# DDR16SS_DDR16SS_CTLPHY_WRAP_CTL_CFG_CTLCFG_0F308000h register map
Vendor: Texas Instruments
Registers are 32-bit, read-write, reset 0x0 unless marked. A register's access mark holds for its fields unless they carry their own. Offsets are as the file gives them; [hi:lo] are bit positions; lines under a group give offsets from that group; {n}, {i} and the like mark numbered series.

## DDR16SS_CTLPHY_WRAP_CTL_CFG_CTLCFG (part 6 of 11)
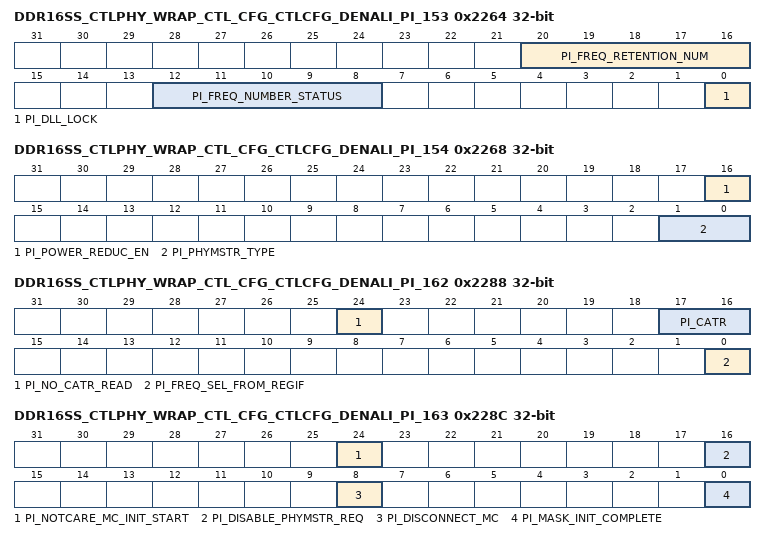
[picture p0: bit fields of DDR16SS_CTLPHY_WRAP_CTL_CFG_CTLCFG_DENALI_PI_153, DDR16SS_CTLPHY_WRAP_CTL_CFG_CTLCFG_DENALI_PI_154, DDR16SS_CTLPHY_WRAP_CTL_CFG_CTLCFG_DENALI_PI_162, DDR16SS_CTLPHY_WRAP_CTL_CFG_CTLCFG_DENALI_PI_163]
0x2264 DDR16SS_CTLPHY_WRAP_CTL_CFG_CTLCFG_DENALI_PI_153 access per field
  [20:16] PI_FREQ_RETENTION_NUM rw — Monitor active freq number in PI for data_retention Reset Source: ctl_amod_g_rst_n
  [12:8] PI_FREQ_NUMBER_STATUS ro — Monitor active freq number in PI. READ-ONLY. Reset Source: ctl_amod_g_rst_n
  [0] PI_DLL_LOCK ro — Monitor dfi_init_complete from PHY. READ-ONLY. Reset Source: ctl_amod_g_rst_n
0x2268 DDR16SS_CTLPHY_WRAP_CTL_CFG_CTLCFG_DENALI_PI_154
  [16] PI_POWER_REDUC_EN — PI Power reduction enable, 1 = enabled. Reset Source: ctl_amod_g_rst_n
  [1:0] PI_PHYMSTR_TYPE — Defines how the controller should set the state of DRAM before turning control of the DFI bus over to the PI. Reset Source: ctl_amod_g_rst_n
{0x2000+4i} DDR16SS_CTLPHY_WRAP_CTL_CFG_CTLCFG_DENALI_PI_{i} access not given reset not defined (i=155..158)
0x227C DDR16SS_CTLPHY_WRAP_CTL_CFG_CTLCFG_DENALI_PI_159
  [23:16] PI_WRLVL_MAX_STROBE_PEND — Defines the maximum number of wrlvl_strobes that be accumulated before an AREF is prevented from being generated. Reset Source: ctl_amod_g_rst_n
0x2280 DDR16SS_CTLPHY_WRAP_CTL_CFG_CTLCFG_DENALI_PI_160
  [8:0] PI_TREFBW_THR — Threshold value to control the AREF command interval. When the number of pending AREF is over this value, the interval is expanded to be tREF/8. Reset Source: ctl_amod_g_rst_n
0x2284 DDR16SS_CTLPHY_WRAP_CTL_CFG_CTLCFG_DENALI_PI_161
  [4:0] PI_FREQ_CHANGE_REG_COPY — In non-DFI 4.0 mode, contains the frequency copy value. Reset Source: ctl_amod_g_rst_n
0x2288 DDR16SS_CTLPHY_WRAP_CTL_CFG_CTLCFG_DENALI_PI_162
  [24] PI_NO_CATR_READ — Defines how the LPDDR4 termination status is determined. 1: PI use PI_CATR to get DRAM CA Termination status. 0: PI reads DRAM MR0.OP7 to get DRAM CA Termination status. Reset Source: ctl_amod_g_rst_n
  [17:16] PI_CATR — It indicates LP4 DRAM CA terminition ON/OFF state. Each bit corresponds to each chip select. 1:ON 0:OFF. This parameter is active when PI_NO_CATR_READ==1. When PI_NO_CATR_READ==0, this param is inactive Reset Source: ctl_amod_g_rst_n
  [0] PI_FREQ_SEL_FROM_REGIF — In non-DFI 4.0 mode, user select the frequency copies from pi_freq_change_reg_copy. Reset Source: ctl_amod_g_rst_n
0x228C DDR16SS_CTLPHY_WRAP_CTL_CFG_CTLCFG_DENALI_PI_163
  [24] PI_NOTCARE_MC_INIT_START — Defines whether PI waits for the controller to initiate dfi_init_start before PI memory initialization, 1: wait for dfi_init_start Reset Source: ctl_amod_g_rst_n
  [16] PI_DISABLE_PHYMSTR_REQ — PI mask dfi_phymstr_req to the controller and get dfi bus without dfi_phymstr_ack, 1: disconnect Reset Source: ctl_amod_g_rst_n
  [8] PI_DISCONNECT_MC — PI disconnects the controller from the PHY, 1: disconnect Reset Source: ctl_amod_g_rst_n
  [0] PI_MASK_INIT_COMPLETE — Enable the masking of the dfi_init_complete signal back to the controller, 1: mask. Reset Source: ctl_amod_g_rst_n
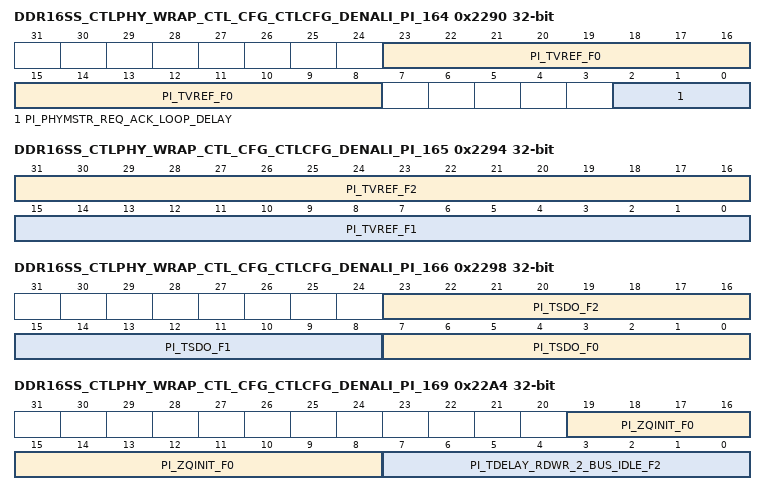
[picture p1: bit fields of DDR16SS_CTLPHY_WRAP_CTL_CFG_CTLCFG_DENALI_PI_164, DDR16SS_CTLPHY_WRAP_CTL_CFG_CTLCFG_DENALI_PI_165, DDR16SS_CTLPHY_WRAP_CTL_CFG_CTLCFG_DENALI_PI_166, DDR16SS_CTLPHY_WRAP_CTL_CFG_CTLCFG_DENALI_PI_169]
0x2290 DDR16SS_CTLPHY_WRAP_CTL_CFG_CTLCFG_DENALI_PI_164
  [23:8] PI_TVREF_F0 — Defines the number of cycles that the PI should wait before issuing the next command after a VREF training MRW command for frequency set 0. Reset Source: ctl_amod_g_rst_n
  [2:0] PI_PHYMSTR_REQ_ACK_LOOP_DELAY — The delay between phymstr_req and inner phymstr_ack when PI_DISABLE_PHYMSTR_REQ set 1 Reset Source: ctl_amod_g_rst_n
0x2294 DDR16SS_CTLPHY_WRAP_CTL_CFG_CTLCFG_DENALI_PI_165
  [31:16] PI_TVREF_F2 — Defines the number of cycles that the PI should wait before issuing the next command after a VREF training MRW command for frequency set 2. Reset Source: ctl_amod_g_rst_n
  [15:0] PI_TVREF_F1 — Defines the number of cycles that the PI should wait before issuing the next command after a VREF training MRW command for frequency set 1. Reset Source: ctl_amod_g_rst_n
0x2298 DDR16SS_CTLPHY_WRAP_CTL_CFG_CTLCFG_DENALI_PI_166
  [23:16] PI_TSDO_F2 — The delay from the read preamble training MRS command to the data strobe drive out for frequency set 2, in PI clocks Reset Source: ctl_amod_g_rst_n
  [15:8] PI_TSDO_F1 — The delay from the read preamble training MRS command to the data strobe drive out for frequency set 1, in PI clocks Reset Source: ctl_amod_g_rst_n
  [7:0] PI_TSDO_F0 — The delay from the read preamble training MRS command to the data strobe drive out for frequency set 0, in PI clocks Reset Source: ctl_amod_g_rst_n
0x229C DDR16SS_CTLPHY_WRAP_CTL_CFG_CTLCFG_DENALI_PI_167
  [7:0] PI_TDELAY_RDWR_2_BUS_IDLE_F0 — The delay from read or write to bus idle for frequency set 0. Recommend setting is: delay time from read command issued to last read data received. Reset Source: ctl_amod_g_rst_n
0x22A0 DDR16SS_CTLPHY_WRAP_CTL_CFG_CTLCFG_DENALI_PI_168
  [7:0] PI_TDELAY_RDWR_2_BUS_IDLE_F1 — The delay from read or write to bus idle for frequency set 1. Recommend setting is: delay time from read command issued to last read data received. Reset Source: ctl_amod_g_rst_n
0x22A4 DDR16SS_CTLPHY_WRAP_CTL_CFG_CTLCFG_DENALI_PI_169
  [19:8] PI_ZQINIT_F0 — Number of cycles needed for a ZQINIT command for frequency set 0. Reset Source: ctl_amod_g_rst_n
  [7:0] PI_TDELAY_RDWR_2_BUS_IDLE_F2 — The delay from read or write to bus idle for frequency set 2. Recommend setting is: delay time from read command issued to last read data received. Reset Source: ctl_amod_g_rst_n
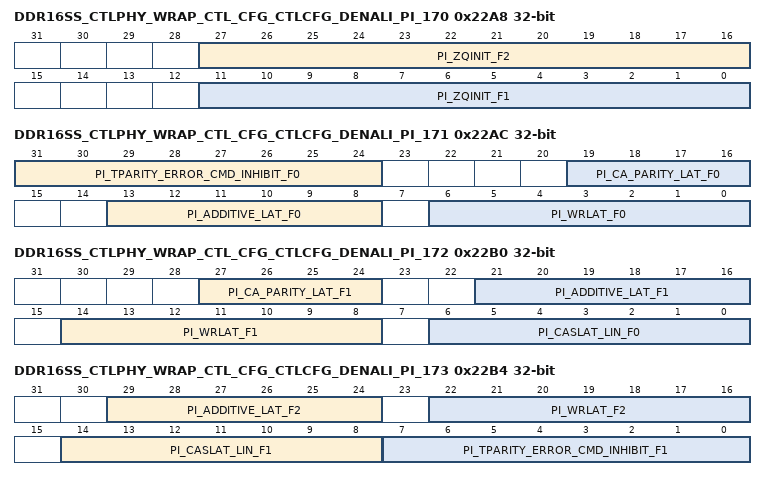
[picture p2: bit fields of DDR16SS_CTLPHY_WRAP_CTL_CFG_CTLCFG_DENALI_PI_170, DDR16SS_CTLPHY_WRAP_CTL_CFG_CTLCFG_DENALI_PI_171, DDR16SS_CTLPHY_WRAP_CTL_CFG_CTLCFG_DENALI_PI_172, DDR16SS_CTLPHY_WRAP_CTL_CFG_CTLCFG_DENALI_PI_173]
0x22A8 DDR16SS_CTLPHY_WRAP_CTL_CFG_CTLCFG_DENALI_PI_170
  [27:16] PI_ZQINIT_F2 — Number of cycles needed for a ZQINIT command for frequency set 2. Reset Source: ctl_amod_g_rst_n
  [11:0] PI_ZQINIT_F1 — Number of cycles needed for a ZQINIT command for frequency set 1. Reset Source: ctl_amod_g_rst_n
0x22AC DDR16SS_CTLPHY_WRAP_CTL_CFG_CTLCFG_DENALI_PI_171
  [31:24] PI_TPARITY_ERROR_CMD_INHIBIT_F0 — Defines the window after the PI receives a parity error during which DRAM commands will not execute for frequency set 0. Reset Source: ctl_amod_g_rst_n
  [19:16] PI_CA_PARITY_LAT_F0 — DRAM CA parity latency value in cycles for frequency set 0. Reset Source: ctl_amod_g_rst_n
  [13:8] PI_ADDITIVE_LAT_F0 — DRAM additive latency value in cycles for frequency set 0. Reset Source: ctl_amod_g_rst_n
  [6:0] PI_WRLAT_F0 — DRAM WRLAT value in cycles for frequency set 0. Reset Source: ctl_amod_g_rst_n
0x22B0 DDR16SS_CTLPHY_WRAP_CTL_CFG_CTLCFG_DENALI_PI_172
  [27:24] PI_CA_PARITY_LAT_F1 — DRAM CA parity latency value in cycles for frequency set 1. Reset Source: ctl_amod_g_rst_n
  [21:16] PI_ADDITIVE_LAT_F1 — DRAM additive latency value in cycles for frequency set 1. Reset Source: ctl_amod_g_rst_n
  [14:8] PI_WRLAT_F1 — DRAM WRLAT value in cycles for frequency set 1. Reset Source: ctl_amod_g_rst_n
  [6:0] PI_CASLAT_LIN_F0 — Sets latency from read command sent to data received from/to controller for frequency set 0. Bit [0] is half-cycle increment and the upper bits define memory CAS latency for the controller. Reset Source: ctl_amod_g_rst_n
0x22B4 DDR16SS_CTLPHY_WRAP_CTL_CFG_CTLCFG_DENALI_PI_173
  [29:24] PI_ADDITIVE_LAT_F2 — DRAM additive latency value in cycles for frequency set 2. Reset Source: ctl_amod_g_rst_n
  [22:16] PI_WRLAT_F2 — DRAM WRLAT value in cycles for frequency set 2. Reset Source: ctl_amod_g_rst_n
  [14:8] PI_CASLAT_LIN_F1 — Sets latency from read command sent to data received from/to controller for frequency set 1. Bit [0] is half-cycle increment and the upper bits define memory CAS latency for the controller. Reset Source: ctl_amod_g_rst_n
  [7:0] PI_TPARITY_ERROR_CMD_INHIBIT_F1 — Defines the window after the PI receives a parity error during which DRAM commands will not execute for frequency set 1. Reset Source: ctl_amod_g_rst_n
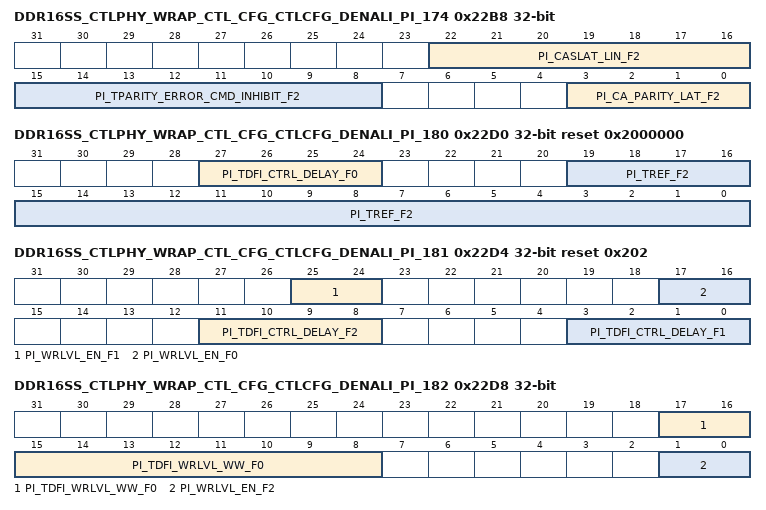
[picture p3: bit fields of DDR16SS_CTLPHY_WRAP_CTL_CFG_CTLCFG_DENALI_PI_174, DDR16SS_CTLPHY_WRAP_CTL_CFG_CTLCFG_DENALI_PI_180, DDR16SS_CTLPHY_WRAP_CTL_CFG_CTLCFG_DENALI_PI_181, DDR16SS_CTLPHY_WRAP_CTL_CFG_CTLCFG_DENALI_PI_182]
0x22B8 DDR16SS_CTLPHY_WRAP_CTL_CFG_CTLCFG_DENALI_PI_174
  [22:16] PI_CASLAT_LIN_F2 — Sets latency from read command sent to data received from/to controller for frequency set 2. Bit [0] is half-cycle increment and the upper bits define memory CAS latency for the controller. Reset Source: ctl_amod_g_rst_n
  [15:8] PI_TPARITY_ERROR_CMD_INHIBIT_F2 — Defines the window after the PI receives a parity error during which DRAM commands will not execute for frequency set 2. Reset Source: ctl_amod_g_rst_n
  [3:0] PI_CA_PARITY_LAT_F2 — DRAM CA parity latency value in cycles for frequency set 2. Reset Source: ctl_amod_g_rst_n
0x22BC DDR16SS_CTLPHY_WRAP_CTL_CFG_CTLCFG_DENALI_PI_175
  [9:0] PI_TRFC_F0 — DRAM tRFC value in memory clocks for frequency set 0. Reset Source: ctl_amod_g_rst_n
0x22C0 DDR16SS_CTLPHY_WRAP_CTL_CFG_CTLCFG_DENALI_PI_176
  [19:0] PI_TREF_F0 — DRAM tREF value in memory clocks for frequency set 0. Reset Source: ctl_amod_g_rst_n
0x22C4 DDR16SS_CTLPHY_WRAP_CTL_CFG_CTLCFG_DENALI_PI_177
  [9:0] PI_TRFC_F1 — DRAM tRFC value in memory clocks for frequency set 1. Reset Source: ctl_amod_g_rst_n
0x22C8 DDR16SS_CTLPHY_WRAP_CTL_CFG_CTLCFG_DENALI_PI_178
  [19:0] PI_TREF_F1 — DRAM tREF value in memory clocks for frequency set 1. Reset Source: ctl_amod_g_rst_n
0x22CC DDR16SS_CTLPHY_WRAP_CTL_CFG_CTLCFG_DENALI_PI_179
  [9:0] PI_TRFC_F2 — DRAM tRFC value in memory clocks for frequency set 2. Reset Source: ctl_amod_g_rst_n
0x22D0 DDR16SS_CTLPHY_WRAP_CTL_CFG_CTLCFG_DENALI_PI_180 reset 0x2000000
  [27:24] PI_TDFI_CTRL_DELAY_F0 — Defines the DFI tCTRL_DELAY timing parameter [in DFI clocks] for frequency set 0, the delay between a DFI command change and a memory command. Reset Source: ctl_amod_g_rst_n
  [19:0] PI_TREF_F2 — DRAM tREF value in memory clocks for frequency set 2. Reset Source: ctl_amod_g_rst_n
0x22D4 DDR16SS_CTLPHY_WRAP_CTL_CFG_CTLCFG_DENALI_PI_181 reset 0x202
  [25:24] PI_WRLVL_EN_F1 — Enable the PI write leveling module for frequency set 1. Bit[1] represents the support when non-initialization. Bit[0]represents the support when initialization. Set to 1 to enable. Reset Source: ctl_amod_g_rst_n
  [17:16] PI_WRLVL_EN_F0 — Enable the PI write leveling module for frequency set 0. Bit[1] represents the support when non-initialization. Bit[0]represents the support when initialization. Set to 1 to enable. Reset Source: ctl_amod_g_rst_n
  [11:8] PI_TDFI_CTRL_DELAY_F2 — Defines the DFI tCTRL_DELAY timing parameter [in DFI clocks] for frequency set 2, the delay between a DFI command change and a memory command. Reset Source: ctl_amod_g_rst_n
  [3:0] PI_TDFI_CTRL_DELAY_F1 — Defines the DFI tCTRL_DELAY timing parameter [in DFI clocks] for frequency set 1, the delay between a DFI command change and a memory command. Reset Source: ctl_amod_g_rst_n
0x22D8 DDR16SS_CTLPHY_WRAP_CTL_CFG_CTLCFG_DENALI_PI_182
  [17:8] PI_TDFI_WRLVL_WW_F0 — Defines the DFI tWRLVL_WW timing parameter [in DFI clocks] for frequency set 0, the minimum cycles between dfi_wrlvl_strobe assertions. Reset Source: ctl_amod_g_rst_n
  [1:0] PI_WRLVL_EN_F2 — Enable the PI write leveling module for frequency set 2. Bit[1] represents the support when non-initialization. Bit[0]represents the support when initialization. Set to 1 to enable. Reset Source: ctl_amod_g_rst_n
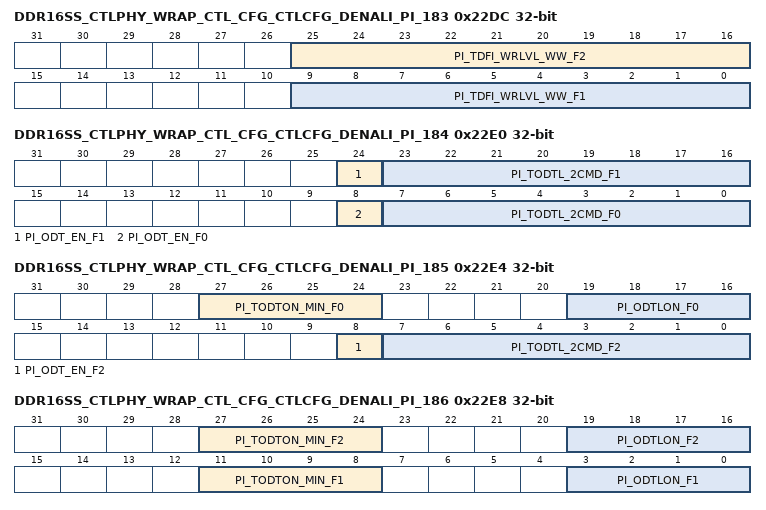
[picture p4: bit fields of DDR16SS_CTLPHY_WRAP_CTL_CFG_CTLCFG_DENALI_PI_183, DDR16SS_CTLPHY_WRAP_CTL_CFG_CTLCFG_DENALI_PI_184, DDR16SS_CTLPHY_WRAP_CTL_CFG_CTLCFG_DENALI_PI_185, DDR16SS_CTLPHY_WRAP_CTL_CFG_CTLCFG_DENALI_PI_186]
0x22DC DDR16SS_CTLPHY_WRAP_CTL_CFG_CTLCFG_DENALI_PI_183
  [25:16] PI_TDFI_WRLVL_WW_F2 — Defines the DFI tWRLVL_WW timing parameter [in DFI clocks] for frequency set 2, the minimum cycles between dfi_wrlvl_strobe assertions. Reset Source: ctl_amod_g_rst_n
  [9:0] PI_TDFI_WRLVL_WW_F1 — Defines the DFI tWRLVL_WW timing parameter [in DFI clocks] for frequency set 1, the minimum cycles between dfi_wrlvl_strobe assertions. Reset Source: ctl_amod_g_rst_n
0x22E0 DDR16SS_CTLPHY_WRAP_CTL_CFG_CTLCFG_DENALI_PI_184
  [24] PI_ODT_EN_F1 — Enable support of DRAM ODT. When enabled, PI will assert and de-assert ODT output to DRAM as needed for frequency set 1. Reset Source: ctl_amod_g_rst_n
  [23:16] PI_TODTL_2CMD_F1 — Defines the DRAM delay from an ODT de-assertion to the next non-write, non-read command for frequency set 1. Reset Source: ctl_amod_g_rst_n
  [8] PI_ODT_EN_F0 — Enable support of DRAM ODT. When enabled, PI will assert and de-assert ODT output to DRAM as needed for frequency set 0. Reset Source: ctl_amod_g_rst_n
  [7:0] PI_TODTL_2CMD_F0 — Defines the DRAM delay from an ODT de-assertion to the next non-write, non-read command for frequency set 0. Reset Source: ctl_amod_g_rst_n
0x22E4 DDR16SS_CTLPHY_WRAP_CTL_CFG_CTLCFG_DENALI_PI_185
  [27:24] PI_TODTON_MIN_F0 — Defines the point in time when the device termination circuit leaves High-Z and ODT resistance begins to turn on for frequency set 0. Reset Source: ctl_amod_g_rst_n
  [19:16] PI_ODTLON_F0 — Defines the latency from a CAS-2 command to the tODTon reference for frequency set 0. Reset Source: ctl_amod_g_rst_n
  [8] PI_ODT_EN_F2 — Enable support of DRAM ODT. When enabled, PI will assert and de-assert ODT output to DRAM as needed for frequency set 2. Reset Source: ctl_amod_g_rst_n
  [7:0] PI_TODTL_2CMD_F2 — Defines the DRAM delay from an ODT de-assertion to the next non-write, non-read command for frequency set 2. Reset Source: ctl_amod_g_rst_n
0x22E8 DDR16SS_CTLPHY_WRAP_CTL_CFG_CTLCFG_DENALI_PI_186
  [27:24] PI_TODTON_MIN_F2 — Defines the point in time when the device termination circuit leaves High-Z and ODT resistance begins to turn on for frequency set 2. Reset Source: ctl_amod_g_rst_n
  [19:16] PI_ODTLON_F2 — Defines the latency from a CAS-2 command to the tODTon reference for frequency set 2. Reset Source: ctl_amod_g_rst_n
  [11:8] PI_TODTON_MIN_F1 — Defines the point in time when the device termination circuit leaves High-Z and ODT resistance begins to turn on for frequency set 1. Reset Source: ctl_amod_g_rst_n
  [3:0] PI_ODTLON_F1 — Defines the latency from a CAS-2 command to the tODTon reference for frequency set 1. Reset Source: ctl_amod_g_rst_n
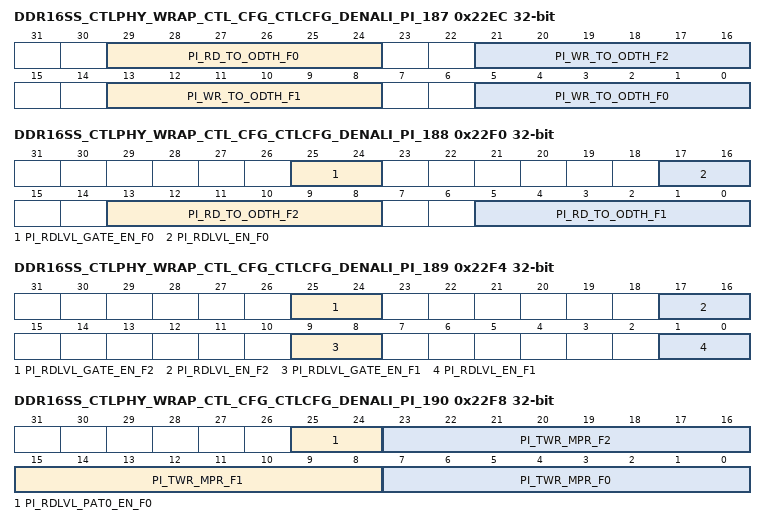
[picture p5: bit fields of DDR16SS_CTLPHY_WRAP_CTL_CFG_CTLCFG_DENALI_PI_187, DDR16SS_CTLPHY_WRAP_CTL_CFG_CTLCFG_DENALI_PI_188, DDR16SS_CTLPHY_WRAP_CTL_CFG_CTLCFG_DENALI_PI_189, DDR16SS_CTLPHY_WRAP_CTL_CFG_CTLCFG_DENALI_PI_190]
0x22EC DDR16SS_CTLPHY_WRAP_CTL_CFG_CTLCFG_DENALI_PI_187
  [29:24] PI_RD_TO_ODTH_F0 — Defines the delay from a read command to ODT assertion for frequency set 0. Reset Source: ctl_amod_g_rst_n
  [21:16] PI_WR_TO_ODTH_F2 — Defines the delay from a write command to ODT assertion for frequency set 2. Reset Source: ctl_amod_g_rst_n
  [13:8] PI_WR_TO_ODTH_F1 — Defines the delay from a write command to ODT assertion for frequency set 1. Reset Source: ctl_amod_g_rst_n
  [5:0] PI_WR_TO_ODTH_F0 — Defines the delay from a write command to ODT assertion for frequency set 0. Reset Source: ctl_amod_g_rst_n
0x22F0 DDR16SS_CTLPHY_WRAP_CTL_CFG_CTLCFG_DENALI_PI_188
  [25:24] PI_RDLVL_GATE_EN_F0 — Enable the PI gate training module for frequency set 0. Bit[1] represents the support when non-initialization. Bit[0]represents the support when initialization. Set to 1 to enable. Reset Source: ctl_amod_g_rst_n
  [17:16] PI_RDLVL_EN_F0 — Enable the PI data eye training module for frequency set 0. Bit[1] represents the support when non-initialization. Bit[0]represents the support when initialization. Set to 1 to enable. Reset Source: ctl_amod_g_rst_n
  [13:8] PI_RD_TO_ODTH_F2 — Defines the delay from a read command to ODT assertion for frequency set 2. Reset Source: ctl_amod_g_rst_n
  [5:0] PI_RD_TO_ODTH_F1 — Defines the delay from a read command to ODT assertion for frequency set 1. Reset Source: ctl_amod_g_rst_n
0x22F4 DDR16SS_CTLPHY_WRAP_CTL_CFG_CTLCFG_DENALI_PI_189
  [25:24] PI_RDLVL_GATE_EN_F2 — Enable the PI gate training module for frequency set 2. Bit[1] represents the support when non-initialization. Bit[0]represents the support when initialization. Set to 1 to enable. Reset Source: ctl_amod_g_rst_n
  [17:16] PI_RDLVL_EN_F2 — Enable the PI data eye training module for frequency set 2. Bit[1] represents the support when non-initialization. Bit[0]represents the support when initialization. Set to 1 to enable. Reset Source: ctl_amod_g_rst_n
  [9:8] PI_RDLVL_GATE_EN_F1 — Enable the PI gate training module for frequency set 1. Bit[1] represents the support when non-initialization. Bit[0]represents the support when initialization. Set to 1 to enable. Reset Source: ctl_amod_g_rst_n
  [1:0] PI_RDLVL_EN_F1 — Enable the PI data eye training module for frequency set 1. Bit[1] represents the support when non-initialization. Bit[0]represents the support when initialization. Set to 1 to enable. Reset Source: ctl_amod_g_rst_n
0x22F8 DDR16SS_CTLPHY_WRAP_CTL_CFG_CTLCFG_DENALI_PI_190
  [25:24] PI_RDLVL_PAT0_EN_F0 — Enable PATTERN-0 for read training for frequency set 0. bit1 for normal; bit0 for initialization. Reset Source: ctl_amod_g_rst_n
  [23:16] PI_TWR_MPR_F2 — Number of cycles after MPR write command and before any other command for frequency set 2. Reset Source: ctl_amod_g_rst_n
  [15:8] PI_TWR_MPR_F1 — Number of cycles after MPR write command and before any other command for frequency set 1. Reset Source: ctl_amod_g_rst_n
  [7:0] PI_TWR_MPR_F0 — Number of cycles after MPR write command and before any other command for frequency set 0. Reset Source: ctl_amod_g_rst_n
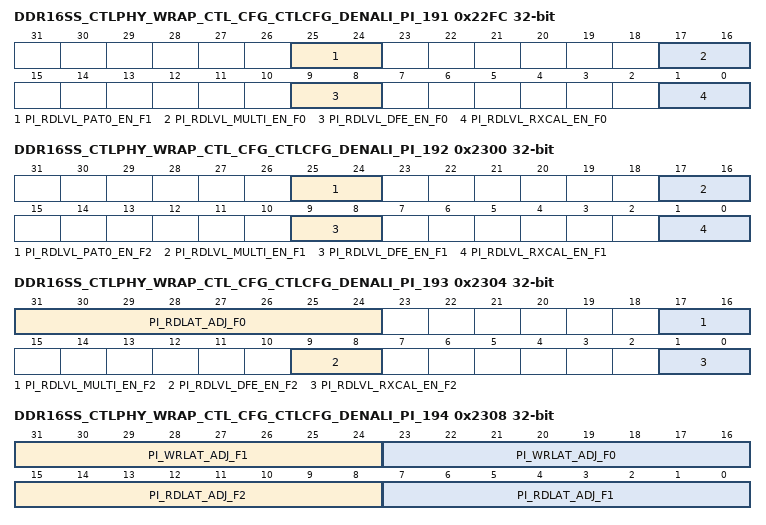
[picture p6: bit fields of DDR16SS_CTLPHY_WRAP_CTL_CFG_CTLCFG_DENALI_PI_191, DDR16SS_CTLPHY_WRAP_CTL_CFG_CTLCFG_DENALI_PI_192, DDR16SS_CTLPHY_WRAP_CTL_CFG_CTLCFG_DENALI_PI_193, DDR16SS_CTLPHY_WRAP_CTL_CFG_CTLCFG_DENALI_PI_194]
0x22FC DDR16SS_CTLPHY_WRAP_CTL_CFG_CTLCFG_DENALI_PI_191
  [25:24] PI_RDLVL_PAT0_EN_F1 — Enable PATTERN-0 for read training for frequency set 1. bit1 for normal; bit0 for initialization. Reset Source: ctl_amod_g_rst_n
  [17:16] PI_RDLVL_MULTI_EN_F0 — Enable Multi-pattern [from PI_RDLVL_PATTERN_START, total PI_RDLVL_PATTERN_NUM] for read training for frequency set 0. bit1 for normal; bit0 for initialization. Reset Source: ctl_amod_g_rst_n
  [9:8] PI_RDLVL_DFE_EN_F0 — Enable DFE [PATTERN 8,9] for read training for frequency set 0. bit1 for normal; bit0 for initialization. Reset Source: ctl_amod_g_rst_n
  [1:0] PI_RDLVL_RXCAL_EN_F0 — Enable RX Offset calibration [PATTERN 14,15] for read training for frequency set 0. bit1 for normal; bit0 for initialization. Reset Source: ctl_amod_g_rst_n
0x2300 DDR16SS_CTLPHY_WRAP_CTL_CFG_CTLCFG_DENALI_PI_192
  [25:24] PI_RDLVL_PAT0_EN_F2 — Enable PATTERN-0 for read training for frequency set 2. bit1 for normal; bit0 for initialization. Reset Source: ctl_amod_g_rst_n
  [17:16] PI_RDLVL_MULTI_EN_F1 — Enable Multi-pattern [from PI_RDLVL_PATTERN_START, total PI_RDLVL_PATTERN_NUM] for read training for frequency set 1. bit1 for normal; bit0 for initialization. Reset Source: ctl_amod_g_rst_n
  [9:8] PI_RDLVL_DFE_EN_F1 — Enable DFE [PATTERN 8,9] for read training for frequency set 1. bit1 for normal; bit0 for initialization. Reset Source: ctl_amod_g_rst_n
  [1:0] PI_RDLVL_RXCAL_EN_F1 — Enable RX Offset calibration [PATTERN 14,15] for read training for frequency set 1. bit1 for normal; bit0 for initialization. Reset Source: ctl_amod_g_rst_n
0x2304 DDR16SS_CTLPHY_WRAP_CTL_CFG_CTLCFG_DENALI_PI_193
  [31:24] PI_RDLAT_ADJ_F0 — Adjusts the relative timing between DFI read commands and the dfi_rddata_en signal for frequency set 0. Reset Source: ctl_amod_g_rst_n
  [17:16] PI_RDLVL_MULTI_EN_F2 — Enable Multi-pattern [from PI_RDLVL_PATTERN_START, total PI_RDLVL_PATTERN_NUM] for read training for frequency set 2. bit1 for normal; bit0 for initialization. Reset Source: ctl_amod_g_rst_n
  [9:8] PI_RDLVL_DFE_EN_F2 — Enable DFE [PATTERN 8,9] for read training for frequency set 2. bit1 for normal; bit0 for initialization. Reset Source: ctl_amod_g_rst_n
  [1:0] PI_RDLVL_RXCAL_EN_F2 — Enable RX Offset calibration [PATTERN 14,15] for read training for frequency set 2. bit1 for normal; bit0 for initialization. Reset Source: ctl_amod_g_rst_n
0x2308 DDR16SS_CTLPHY_WRAP_CTL_CFG_CTLCFG_DENALI_PI_194
  [31:24] PI_WRLAT_ADJ_F1 — Adjusts the relative timing in memory clocks between DFI write commands and the dfi_wrdata_en signal for frequency set 1. Reset Source: ctl_amod_g_rst_n
  [23:16] PI_WRLAT_ADJ_F0 — Adjusts the relative timing in memory clocks between DFI write commands and the dfi_wrdata_en signal for frequency set 0. Reset Source: ctl_amod_g_rst_n
  [15:8] PI_RDLAT_ADJ_F2 — Adjusts the relative timing between DFI read commands and the dfi_rddata_en signal for frequency set 2. Reset Source: ctl_amod_g_rst_n
  [7:0] PI_RDLAT_ADJ_F1 — Adjusts the relative timing between DFI read commands and the dfi_rddata_en signal for frequency set 1. Reset Source: ctl_amod_g_rst_n
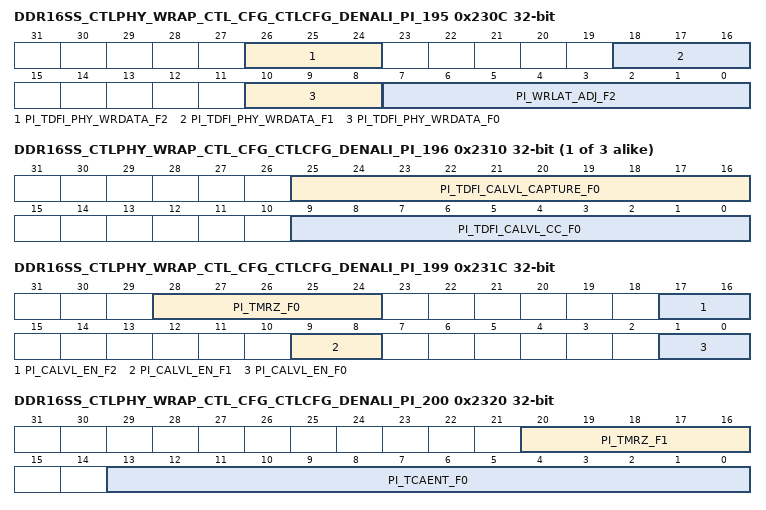
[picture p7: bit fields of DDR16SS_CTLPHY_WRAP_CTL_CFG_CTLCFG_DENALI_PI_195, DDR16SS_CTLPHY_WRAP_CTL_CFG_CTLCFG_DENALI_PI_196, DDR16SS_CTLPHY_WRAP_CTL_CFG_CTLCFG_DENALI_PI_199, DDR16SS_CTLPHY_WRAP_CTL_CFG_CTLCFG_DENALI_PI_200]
0x230C DDR16SS_CTLPHY_WRAP_CTL_CFG_CTLCFG_DENALI_PI_195
  [26:24] PI_TDFI_PHY_WRDATA_F2 — Defines the DFI tPHY_WRDATA timing parameter [in DFI PHY clocks] for frequency set 2, the maximum cycles between a dfi_wrdata_en assertion and a dfi_wrdata signal. Reset Source: ctl_amod_g_rst_n
  [18:16] PI_TDFI_PHY_WRDATA_F1 — Defines the DFI tPHY_WRDATA timing parameter [in DFI PHY clocks] for frequency set 1, the maximum cycles between a dfi_wrdata_en assertion and a dfi_wrdata signal. Reset Source: ctl_amod_g_rst_n
  [10:8] PI_TDFI_PHY_WRDATA_F0 — Defines the DFI tPHY_WRDATA timing parameter [in DFI PHY clocks] for frequency set 0, the maximum cycles between a dfi_wrdata_en assertion and a dfi_wrdata signal. Reset Source: ctl_amod_g_rst_n
  [7:0] PI_WRLAT_ADJ_F2 — Adjusts the relative timing in memory clocks between DFI write commands and the dfi_wrdata_en signal for frequency set 2. Reset Source: ctl_amod_g_rst_n
{0x2000+4i} DDR16SS_CTLPHY_WRAP_CTL_CFG_CTLCFG_DENALI_PI_{i} (i=196..198)
  [25:16] PI_TDFI_CALVL_CAPTURE_F{i-196} — Defines the DFI tCALVL_CAPTURE timing parameter [in DFI clocks] for frequency set {i-196}, the minimum cycles between a calibration command and a dfi_calvl_capture pulse. Reset Source: ctl_amod_g_rst_n
  [9:0] PI_TDFI_CALVL_CC_F{i-196} — Defines the DFI tCALVL_CC timing parameter [in DFI clocks] for frequency set {i-196}, the minimum cycles between calibration commands. Reset Source: ctl_amod_g_rst_n
0x231C DDR16SS_CTLPHY_WRAP_CTL_CFG_CTLCFG_DENALI_PI_199
  [28:24] PI_TMRZ_F0 — Defines the delay between a MRW CA exit command and the DQ tristate in memory clocks for frequency set 0. Reset Source: ctl_amod_g_rst_n
  [17:16] PI_CALVL_EN_F2 — Enable the PI CA training module. Bit[1] represents the support when non-initialization for frequency set 2. Bit[0]represents the support when initialization. Set to 1 to enable. Reset Source: ctl_amod_g_rst_n
  [9:8] PI_CALVL_EN_F1 — Enable the PI CA training module. Bit[1] represents the support when non-initialization for frequency set 1. Bit[0]represents the support when initialization. Set to 1 to enable. Reset Source: ctl_amod_g_rst_n
  [1:0] PI_CALVL_EN_F0 — Enable the PI CA training module. Bit[1] represents the support when non-initialization for frequency set 0. Bit[0]represents the support when initialization. Set to 1 to enable. Reset Source: ctl_amod_g_rst_n
0x2320 DDR16SS_CTLPHY_WRAP_CTL_CFG_CTLCFG_DENALI_PI_200
  [20:16] PI_TMRZ_F1 — Defines the delay between a MRW CA exit command and the DQ tristate in memory clocks for frequency set 1. Reset Source: ctl_amod_g_rst_n
  [13:0] PI_TCAENT_F0 — Defines the DRAM tCAENT term, in memory clocks for frequency set 0. Reset Source: ctl_amod_g_rst_n
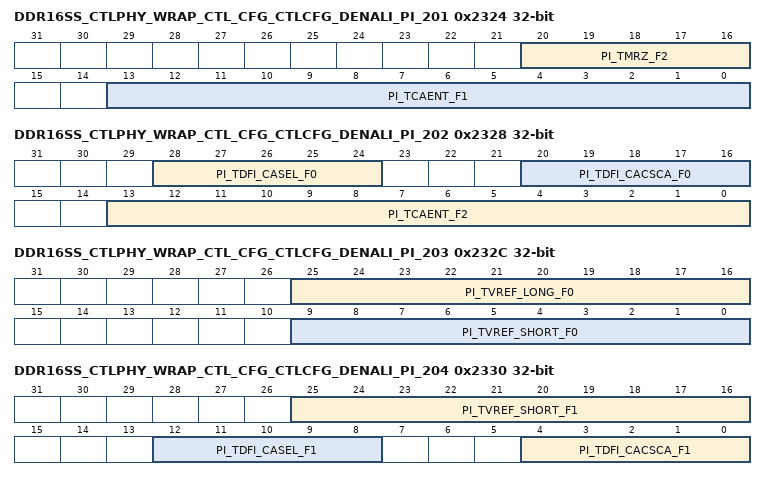
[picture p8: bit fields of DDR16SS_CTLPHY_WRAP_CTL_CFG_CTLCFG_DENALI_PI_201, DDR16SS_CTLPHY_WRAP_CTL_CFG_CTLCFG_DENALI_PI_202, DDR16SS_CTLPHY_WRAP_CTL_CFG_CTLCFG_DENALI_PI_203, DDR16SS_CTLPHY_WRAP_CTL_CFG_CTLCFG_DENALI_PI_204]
0x2324 DDR16SS_CTLPHY_WRAP_CTL_CFG_CTLCFG_DENALI_PI_201
  [20:16] PI_TMRZ_F2 — Defines the delay between a MRW CA exit command and the DQ tristate in memory clocks for frequency set 2. Reset Source: ctl_amod_g_rst_n
  [13:0] PI_TCAENT_F1 — Defines the DRAM tCAENT term, in memory clocks for frequency set 1. Reset Source: ctl_amod_g_rst_n
0x2328 DDR16SS_CTLPHY_WRAP_CTL_CFG_CTLCFG_DENALI_PI_202
  [28:24] PI_TDFI_CASEL_F0 — Defines the DFI tcalvl_ca_sel timing parameter, the width of dfi_calvl_ca_sel in PHY DFI clock cycles for frequency set 0. Reset Source: ctl_amod_g_rst_n
  [20:16] PI_TDFI_CACSCA_F0 — Defines the DFI tcalvl_cs_ca timing parameter, the number of PHY DFI clocks from the assertion of dfi_calvl_ca_sel to the assertion of dfi_cs for frequency set 0. Reset Source: ctl_amod_g_rst_n
  [13:0] PI_TCAENT_F2 — Defines the DRAM tCAENT term, in memory clocks for frequency set 2. Reset Source: ctl_amod_g_rst_n
0x232C DDR16SS_CTLPHY_WRAP_CTL_CFG_CTLCFG_DENALI_PI_203
  [25:16] PI_TVREF_LONG_F0 — Defines the delay in PI clock cycles between the dfi_calvl_strobe to the next command if the pi_calvl_vref_stepsize parameter gt 1 for frequency set 0. Reset Source: ctl_amod_g_rst_n
  [9:0] PI_TVREF_SHORT_F0 — Defines the delay in PI clock cycles between the dfi_calvl_strobe to the next command if the pi_calvl_vref_stepsize parameter = 1 for frequency set 0. Reset Source: ctl_amod_g_rst_n
0x2330 DDR16SS_CTLPHY_WRAP_CTL_CFG_CTLCFG_DENALI_PI_204
  [25:16] PI_TVREF_SHORT_F1 — Defines the delay in PI clock cycles between the dfi_calvl_strobe to the next command if the pi_calvl_vref_stepsize parameter = 1 for frequency set 1. Reset Source: ctl_amod_g_rst_n
  [12:8] PI_TDFI_CASEL_F1 — Defines the DFI tcalvl_ca_sel timing parameter, the width of dfi_calvl_ca_sel in PHY DFI clock cycles for frequency set 1. Reset Source: ctl_amod_g_rst_n
  [4:0] PI_TDFI_CACSCA_F1 — Defines the DFI tcalvl_cs_ca timing parameter, the number of PHY DFI clocks from the assertion of dfi_calvl_ca_sel to the assertion of dfi_cs for frequency set 1. Reset Source: ctl_amod_g_rst_n
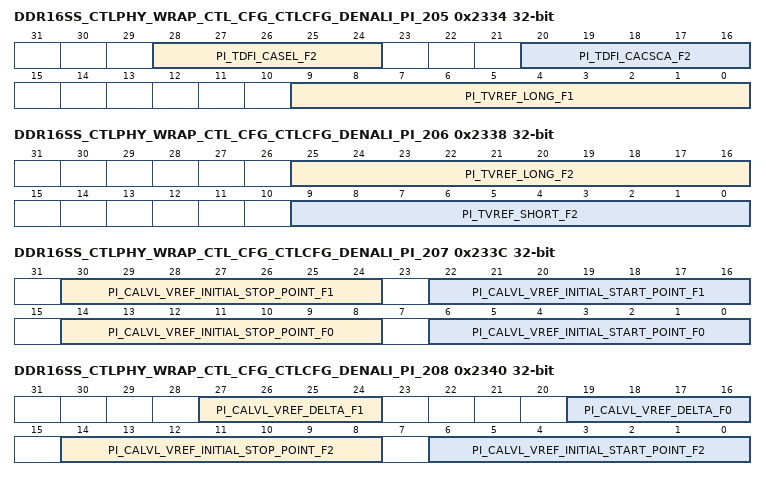
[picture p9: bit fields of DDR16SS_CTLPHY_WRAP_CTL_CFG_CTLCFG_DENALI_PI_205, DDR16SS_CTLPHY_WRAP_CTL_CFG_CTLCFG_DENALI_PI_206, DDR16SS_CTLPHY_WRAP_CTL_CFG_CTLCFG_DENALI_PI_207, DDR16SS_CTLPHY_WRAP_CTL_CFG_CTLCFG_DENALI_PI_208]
0x2334 DDR16SS_CTLPHY_WRAP_CTL_CFG_CTLCFG_DENALI_PI_205
  [28:24] PI_TDFI_CASEL_F2 — Defines the DFI tcalvl_ca_sel timing parameter, the width of dfi_calvl_ca_sel in PHY DFI clock cycles for frequency set 2. Reset Source: ctl_amod_g_rst_n
  [20:16] PI_TDFI_CACSCA_F2 — Defines the DFI tcalvl_cs_ca timing parameter, the number of PHY DFI clocks from the assertion of dfi_calvl_ca_sel to the assertion of dfi_cs for frequency set 2. Reset Source: ctl_amod_g_rst_n
  [9:0] PI_TVREF_LONG_F1 — Defines the delay in PI clock cycles between the dfi_calvl_strobe to the next command if the pi_calvl_vref_stepsize parameter gt 1 for frequency set 1. Reset Source: ctl_amod_g_rst_n
0x2338 DDR16SS_CTLPHY_WRAP_CTL_CFG_CTLCFG_DENALI_PI_206
  [25:16] PI_TVREF_LONG_F2 — Defines the delay in PI clock cycles between the dfi_calvl_strobe to the next command if the pi_calvl_vref_stepsize parameter gt 1 for frequency set 2. Reset Source: ctl_amod_g_rst_n
  [9:0] PI_TVREF_SHORT_F2 — Defines the delay in PI clock cycles between the dfi_calvl_strobe to the next command if the pi_calvl_vref_stepsize parameter = 1 for frequency set 2. Reset Source: ctl_amod_g_rst_n
0x233C DDR16SS_CTLPHY_WRAP_CTL_CFG_CTLCFG_DENALI_PI_207
  [30:24] PI_CALVL_VREF_INITIAL_STOP_POINT_F1 — The end point of initial training for the Vref[ca] training for frequency set 1 { vrefca_range, vref_ca_setting[5:0]}. Reset Source: ctl_amod_g_rst_n
  [22:16] PI_CALVL_VREF_INITIAL_START_POINT_F1 — The start point of initial training for the Vref[ca] training for frequency set 1 { vrefca_range, vref_ca_setting[5:0]}. Reset Source: ctl_amod_g_rst_n
  [14:8] PI_CALVL_VREF_INITIAL_STOP_POINT_F0 — The end point of initial training for the Vref[ca] training for frequency set 0 { vrefca_range, vref_ca_setting[5:0]}. Reset Source: ctl_amod_g_rst_n
  [6:0] PI_CALVL_VREF_INITIAL_START_POINT_F0 — The start point of initial training for the Vref[ca] training for frequency set 0 { vrefca_range, vref_ca_setting[5:0]}. Reset Source: ctl_amod_g_rst_n
0x2340 DDR16SS_CTLPHY_WRAP_CTL_CFG_CTLCFG_DENALI_PI_208
  [27:24] PI_CALVL_VREF_DELTA_F1 — The delta fro the current CA vref for non-initial CA training for frequency set 1. Reset Source: ctl_amod_g_rst_n
  [19:16] PI_CALVL_VREF_DELTA_F0 — The delta fro the current CA vref for non-initial CA training for frequency set 0. Reset Source: ctl_amod_g_rst_n
  [14:8] PI_CALVL_VREF_INITIAL_STOP_POINT_F2 — The end point of initial training for the Vref[ca] training for frequency set 2 { vrefca_range, vref_ca_setting[5:0]}. Reset Source: ctl_amod_g_rst_n
  [6:0] PI_CALVL_VREF_INITIAL_START_POINT_F2 — The start point of initial training for the Vref[ca] training for frequency set 2 { vrefca_range, vref_ca_setting[5:0]}. Reset Source: ctl_amod_g_rst_n
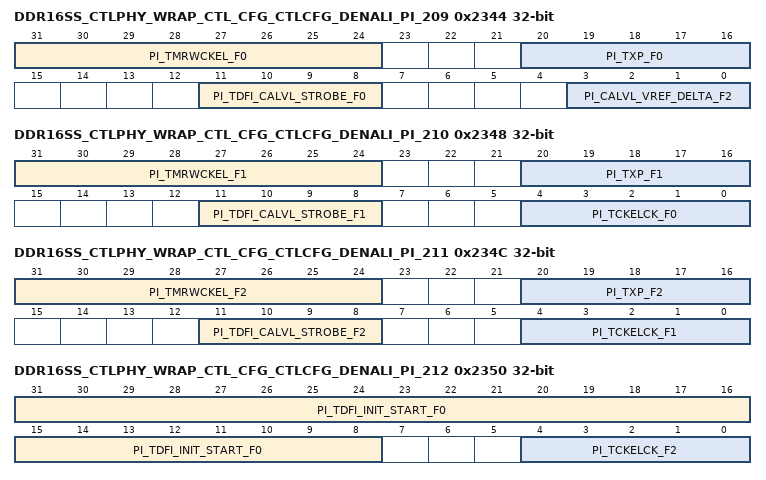
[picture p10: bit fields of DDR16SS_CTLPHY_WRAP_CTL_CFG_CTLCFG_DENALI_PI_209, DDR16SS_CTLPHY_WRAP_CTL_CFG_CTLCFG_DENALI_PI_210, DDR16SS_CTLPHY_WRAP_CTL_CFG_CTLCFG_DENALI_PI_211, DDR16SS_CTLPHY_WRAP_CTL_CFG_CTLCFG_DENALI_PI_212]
0x2344 DDR16SS_CTLPHY_WRAP_CTL_CFG_CTLCFG_DENALI_PI_209
  [31:24] PI_TMRWCKEL_F0 — Valid Clock and CS Requirement before CKE deassert after MRW Command for frequency set 0. Reset Source: ctl_amod_g_rst_n
  [20:16] PI_TXP_F0 — CKE assert to next valid command delay for frequency set 0. Reset Source: ctl_amod_g_rst_n
  [11:8] PI_TDFI_CALVL_STROBE_F0 — Minimum number of DFI PHY clocks from dfi_calvl_data to dfi_calvl_strobe mode for frequency set 0. Reset Source: ctl_amod_g_rst_n
  [3:0] PI_CALVL_VREF_DELTA_F2 — The delta fro the current CA vref for non-initial CA training for frequency set 2. Reset Source: ctl_amod_g_rst_n
0x2348 DDR16SS_CTLPHY_WRAP_CTL_CFG_CTLCFG_DENALI_PI_210
  [31:24] PI_TMRWCKEL_F1 — Valid Clock and CS Requirement before CKE deassert after MRW Command for frequency set 1. Reset Source: ctl_amod_g_rst_n
  [20:16] PI_TXP_F1 — CKE assert to next valid command delay for frequency set 1. Reset Source: ctl_amod_g_rst_n
  [11:8] PI_TDFI_CALVL_STROBE_F1 — Minimum number of DFI PHY clocks from dfi_calvl_data to dfi_calvl_strobe mode for frequency set 1. Reset Source: ctl_amod_g_rst_n
  [4:0] PI_TCKELCK_F0 — Valid Clock Requirement after CKE deassert for frequency set 0. Reset Source: ctl_amod_g_rst_n
0x234C DDR16SS_CTLPHY_WRAP_CTL_CFG_CTLCFG_DENALI_PI_211
  [31:24] PI_TMRWCKEL_F2 — Valid Clock and CS Requirement before CKE deassert after MRW Command for frequency set 2. Reset Source: ctl_amod_g_rst_n
  [20:16] PI_TXP_F2 — CKE assert to next valid command delay for frequency set 2. Reset Source: ctl_amod_g_rst_n
  [11:8] PI_TDFI_CALVL_STROBE_F2 — Minimum number of DFI PHY clocks from dfi_calvl_data to dfi_calvl_strobe mode for frequency set 2. Reset Source: ctl_amod_g_rst_n
  [4:0] PI_TCKELCK_F1 — Valid Clock Requirement after CKE deassert for frequency set 1. Reset Source: ctl_amod_g_rst_n
0x2350 DDR16SS_CTLPHY_WRAP_CTL_CFG_CTLCFG_DENALI_PI_212
  [31:8] PI_TDFI_INIT_START_F0 — Defines the DFI tINIT_START timing parameter [in DFI clocks] for frequency set 0, the maximum number of cycles between a dfi_init_start assertion and a dfi_init_complete de-assertion from the PHY. Reset Source: ctl_amod_g_rst_n
  [4:0] PI_TCKELCK_F2 — Valid Clock Requirement after CKE deassert for frequency set 2. Reset Source: ctl_amod_g_rst_n
0x2354 DDR16SS_CTLPHY_WRAP_CTL_CFG_CTLCFG_DENALI_PI_213
  [23:0] PI_TDFI_INIT_COMPLETE_F0 — Defines the DFI tINIT_COMPLETE timing parameter [in DFI clocks] for frequency set 0, the maximum cycles between a dfi_init_start de-assertion and a dfi_init_complete assertion from the PHY. Reset Source: ctl_amod_g_rst_n
0x2358 DDR16SS_CTLPHY_WRAP_CTL_CFG_CTLCFG_DENALI_PI_214
  [23:0] PI_TDFI_INIT_START_F1 — Defines the DFI tINIT_START timing parameter [in DFI clocks] for frequency set 1, the maximum number of cycles between a dfi_init_start assertion and a dfi_init_complete de-assertion from the PHY. Reset Source: ctl_amod_g_rst_n
0x235C DDR16SS_CTLPHY_WRAP_CTL_CFG_CTLCFG_DENALI_PI_215
  [23:0] PI_TDFI_INIT_COMPLETE_F1 — Defines the DFI tINIT_COMPLETE timing parameter [in DFI clocks] for frequency set 1, the maximum cycles between a dfi_init_start de-assertion and a dfi_init_complete assertion from the PHY. Reset Source: ctl_amod_g_rst_n
0x2360 DDR16SS_CTLPHY_WRAP_CTL_CFG_CTLCFG_DENALI_PI_216
  [23:0] PI_TDFI_INIT_START_F2 — Defines the DFI tINIT_START timing parameter [in DFI clocks] for frequency set 2, the maximum number of cycles between a dfi_init_start assertion and a dfi_init_complete de-assertion from the PHY. Reset Source: ctl_amod_g_rst_n
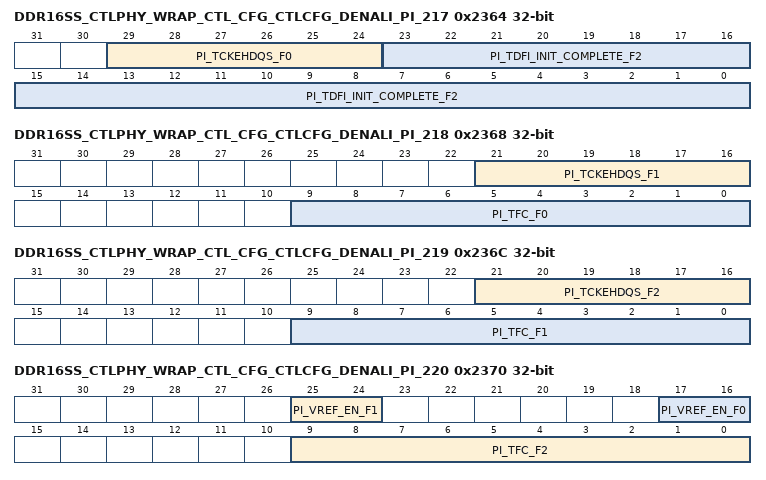
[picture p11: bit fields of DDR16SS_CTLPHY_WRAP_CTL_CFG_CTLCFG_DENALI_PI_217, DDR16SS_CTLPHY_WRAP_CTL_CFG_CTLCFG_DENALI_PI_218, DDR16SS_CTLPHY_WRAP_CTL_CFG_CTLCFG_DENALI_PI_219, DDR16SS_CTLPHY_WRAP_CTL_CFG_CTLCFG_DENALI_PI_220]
0x2364 DDR16SS_CTLPHY_WRAP_CTL_CFG_CTLCFG_DENALI_PI_217
  [29:24] PI_TCKEHDQS_F0 — The DRAM timing tCKEHDQS, minimum delay from CKE high to strobe high impedance for frequency set 0. Reset Source: ctl_amod_g_rst_n
  [23:0] PI_TDFI_INIT_COMPLETE_F2 — Defines the DFI tINIT_COMPLETE timing parameter [in DFI clocks] for frequency set 2, the maximum cycles between a dfi_init_start de-assertion and a dfi_init_complete assertion from the PHY. Reset Source: ctl_amod_g_rst_n
0x2368 DDR16SS_CTLPHY_WRAP_CTL_CFG_CTLCFG_DENALI_PI_218
  [21:16] PI_TCKEHDQS_F1 — The DRAM timing tCKEHDQS, minimum delay from CKE high to strobe high impedance for frequency set 1. Reset Source: ctl_amod_g_rst_n
  [9:0] PI_TFC_F0 — The delay in PHY clock cycles from setting MR13.OP7 to any valid command for frequency set 0. Reset Source: ctl_amod_g_rst_n
0x236C DDR16SS_CTLPHY_WRAP_CTL_CFG_CTLCFG_DENALI_PI_219
  [21:16] PI_TCKEHDQS_F2 — The DRAM timing tCKEHDQS, minimum delay from CKE high to strobe high impedance for frequency set 2. Reset Source: ctl_amod_g_rst_n
  [9:0] PI_TFC_F1 — The delay in PHY clock cycles from setting MR13.OP7 to any valid command for frequency set 1. Reset Source: ctl_amod_g_rst_n
0x2370 DDR16SS_CTLPHY_WRAP_CTL_CFG_CTLCFG_DENALI_PI_220
  [25:24] PI_VREF_EN_F1 — Enable VREF training during power-up initialization for frequency set 1. Bit[1] represents the support when non-initialization. Bit[0]represents the support when initialization. Set to 1 to enable. Reset Source: ctl_amod_g_rst_n
  [17:16] PI_VREF_EN_F0 — Enable VREF training during power-up initialization for frequency set 0. Bit[1] represents the support when non-initialization. Bit[0]represents the support when initialization. Set to 1 to enable. Reset Source: ctl_amod_g_rst_n
  [9:0] PI_TFC_F2 — The delay in PHY clock cycles from setting MR13.OP7 to any valid command for frequency set 2. Reset Source: ctl_amod_g_rst_n
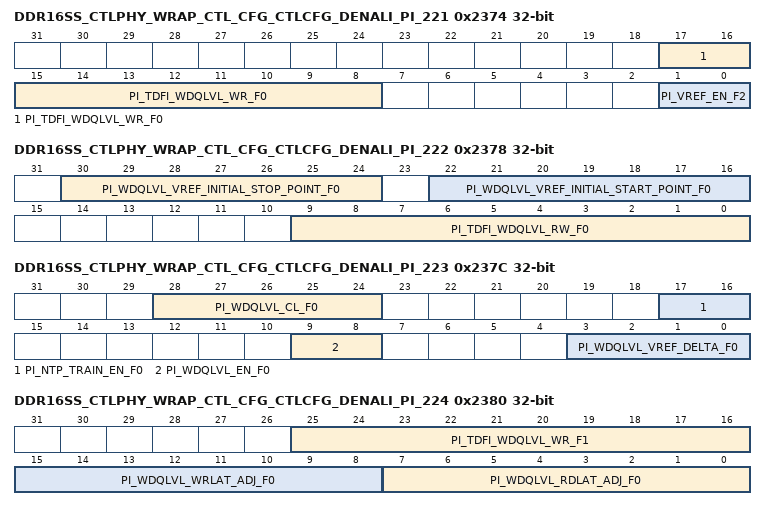
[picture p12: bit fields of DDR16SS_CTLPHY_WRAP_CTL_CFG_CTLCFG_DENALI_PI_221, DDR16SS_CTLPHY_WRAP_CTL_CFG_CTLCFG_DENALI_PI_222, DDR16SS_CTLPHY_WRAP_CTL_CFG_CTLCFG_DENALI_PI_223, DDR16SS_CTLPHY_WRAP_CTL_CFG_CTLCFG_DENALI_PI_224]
0x2374 DDR16SS_CTLPHY_WRAP_CTL_CFG_CTLCFG_DENALI_PI_221
  [17:8] PI_TDFI_WDQLVL_WR_F0 — Switch time from write to read for frequency set 0. Reset Source: ctl_amod_g_rst_n
  [1:0] PI_VREF_EN_F2 — Enable VREF training during power-up initialization for frequency set 2. Bit[1] represents the support when non-initialization. Bit[0]represents the support when initialization. Set to 1 to enable. Reset Source: ctl_amod_g_rst_n
0x2378 DDR16SS_CTLPHY_WRAP_CTL_CFG_CTLCFG_DENALI_PI_222
  [30:24] PI_WDQLVL_VREF_INITIAL_STOP_POINT_F0 — Write DQ training vref initial training stop value for frequency set 0. Reset Source: ctl_amod_g_rst_n
  [22:16] PI_WDQLVL_VREF_INITIAL_START_POINT_F0 — Write DQ training vref initial training start value for frequency set 0. Reset Source: ctl_amod_g_rst_n
  [9:0] PI_TDFI_WDQLVL_RW_F0 — Switch time from read to write for frequency set 0. Reset Source: ctl_amod_g_rst_n
0x237C DDR16SS_CTLPHY_WRAP_CTL_CFG_CTLCFG_DENALI_PI_223
  [28:24] PI_WDQLVL_CL_F0 — CL when the Read DBI disabled while doing WDQ training for frequency set 0. Reset Source: ctl_amod_g_rst_n
  [17:16] PI_NTP_TRAIN_EN_F0 — Indicates whether the no topology WDQ training is enabled. Bit[1] represents the support when non-initialization. Bit[0]represents the support when initialization. Reset Source: ctl_amod_g_rst_n
  [9:8] PI_WDQLVL_EN_F0 — Indicates if Write DQ leveling is enabled for frequency set 0. Bit[1] represents the support when non-initialization. Bit[0]represents the support when initialization. Reset Source: ctl_amod_g_rst_n
  [3:0] PI_WDQLVL_VREF_DELTA_F0 — The delta from the current Write DQ vref adjustment for non-initial wdq training for frequency set 0. Reset Source: ctl_amod_g_rst_n
0x2380 DDR16SS_CTLPHY_WRAP_CTL_CFG_CTLCFG_DENALI_PI_224
  [25:16] PI_TDFI_WDQLVL_WR_F1 — Switch time from write to read for frequency set 1. Reset Source: ctl_amod_g_rst_n
  [15:8] PI_WDQLVL_WRLAT_ADJ_F0 — Adjusted Tdfi_wrdata_en value for PHY read timing when read dbi disabled for frequency set 0, used for WDQ training. Reset Source: ctl_amod_g_rst_n
  [7:0] PI_WDQLVL_RDLAT_ADJ_F0 — Adjusted Tdfi_rddata_en value for PHY read timing when read dbi disabled for frequency set 0, used for WDQ training. Reset Source: ctl_amod_g_rst_n
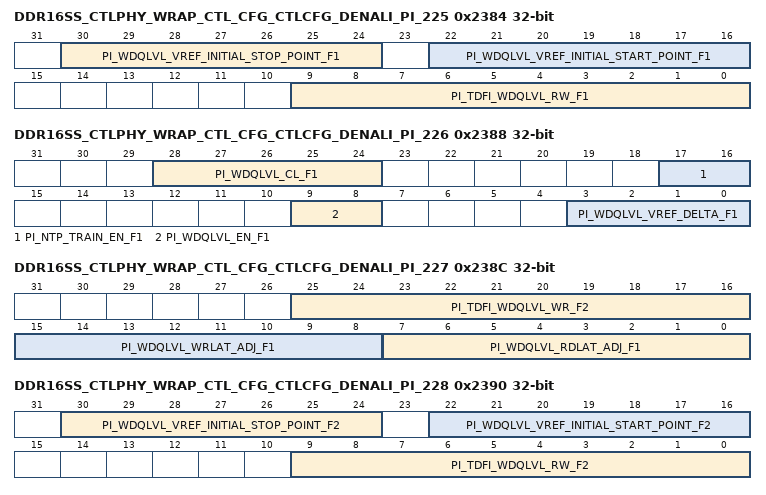
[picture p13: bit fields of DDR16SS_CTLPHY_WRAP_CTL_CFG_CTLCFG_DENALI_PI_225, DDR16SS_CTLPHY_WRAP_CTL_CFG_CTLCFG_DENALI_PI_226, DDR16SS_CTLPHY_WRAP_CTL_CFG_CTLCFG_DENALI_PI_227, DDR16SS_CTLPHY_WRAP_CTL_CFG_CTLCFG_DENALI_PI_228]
0x2384 DDR16SS_CTLPHY_WRAP_CTL_CFG_CTLCFG_DENALI_PI_225
  [30:24] PI_WDQLVL_VREF_INITIAL_STOP_POINT_F1 — Write DQ training vref initial training stop value for frequency set 1. Reset Source: ctl_amod_g_rst_n
  [22:16] PI_WDQLVL_VREF_INITIAL_START_POINT_F1 — Write DQ training vref initial training start value for frequency set 1. Reset Source: ctl_amod_g_rst_n
  [9:0] PI_TDFI_WDQLVL_RW_F1 — Switch time from read to write for frequency set 1. Reset Source: ctl_amod_g_rst_n
0x2388 DDR16SS_CTLPHY_WRAP_CTL_CFG_CTLCFG_DENALI_PI_226
  [28:24] PI_WDQLVL_CL_F1 — CL when the Read DBI disabled while doing WDQ training for frequency set 1. Reset Source: ctl_amod_g_rst_n
  [17:16] PI_NTP_TRAIN_EN_F1 — Indicates whether the no topology WDQ training is enabled. Bit[1] represents the support when non-initialization. Bit[0]represents the support when initialization. Reset Source: ctl_amod_g_rst_n
  [9:8] PI_WDQLVL_EN_F1 — Indicates if Write DQ leveling is enabled for frequency set 1. Bit[1] represents the support when non-initialization. Bit[0]represents the support when initialization. Reset Source: ctl_amod_g_rst_n
  [3:0] PI_WDQLVL_VREF_DELTA_F1 — The delta from the current Write DQ vref adjustment for non-initial wdq training for frequency set 1. Reset Source: ctl_amod_g_rst_n
0x238C DDR16SS_CTLPHY_WRAP_CTL_CFG_CTLCFG_DENALI_PI_227
  [25:16] PI_TDFI_WDQLVL_WR_F2 — Switch time from write to read for frequency set 2. Reset Source: ctl_amod_g_rst_n
  [15:8] PI_WDQLVL_WRLAT_ADJ_F1 — Adjusted Tdfi_wrdata_en value for PHY read timing when read dbi disabled for frequency set 1, used for WDQ training. Reset Source: ctl_amod_g_rst_n
  [7:0] PI_WDQLVL_RDLAT_ADJ_F1 — Adjusted Tdfi_rddata_en value for PHY read timing when read dbi disabled for frequency set 1, used for WDQ training. Reset Source: ctl_amod_g_rst_n
0x2390 DDR16SS_CTLPHY_WRAP_CTL_CFG_CTLCFG_DENALI_PI_228
  [30:24] PI_WDQLVL_VREF_INITIAL_STOP_POINT_F2 — Write DQ training vref initial training stop value for frequency set 2. Reset Source: ctl_amod_g_rst_n
  [22:16] PI_WDQLVL_VREF_INITIAL_START_POINT_F2 — Write DQ training vref initial training start value for frequency set 2. Reset Source: ctl_amod_g_rst_n
  [9:0] PI_TDFI_WDQLVL_RW_F2 — Switch time from read to write for frequency set 2. Reset Source: ctl_amod_g_rst_n
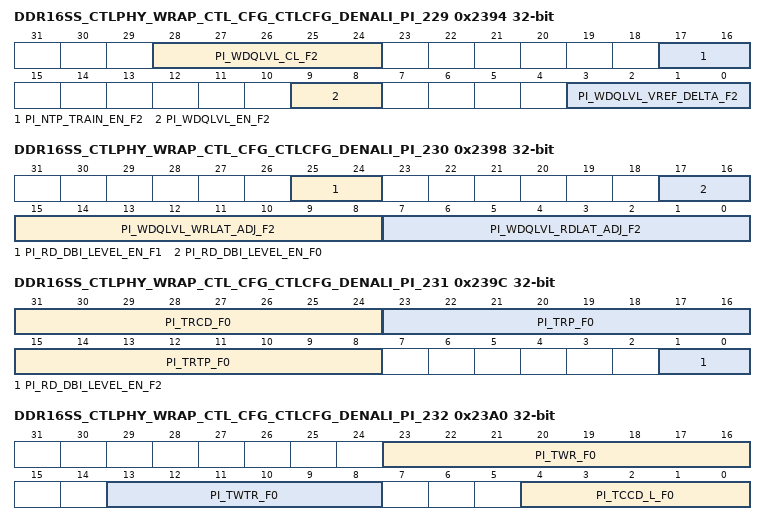
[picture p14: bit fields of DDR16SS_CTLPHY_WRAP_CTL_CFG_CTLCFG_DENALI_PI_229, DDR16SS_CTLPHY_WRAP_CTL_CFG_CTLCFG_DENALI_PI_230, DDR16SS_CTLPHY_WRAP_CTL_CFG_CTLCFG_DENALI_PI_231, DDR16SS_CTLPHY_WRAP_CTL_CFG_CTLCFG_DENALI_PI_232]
0x2394 DDR16SS_CTLPHY_WRAP_CTL_CFG_CTLCFG_DENALI_PI_229
  [28:24] PI_WDQLVL_CL_F2 — CL when the Read DBI disabled while doing WDQ training for frequency set 2. Reset Source: ctl_amod_g_rst_n
  [17:16] PI_NTP_TRAIN_EN_F2 — Indicates whether the no topology WDQ training is enabled. Bit[1] represents the support when non-initialization. Bit[0]represents the support when initialization. Reset Source: ctl_amod_g_rst_n
  [9:8] PI_WDQLVL_EN_F2 — Indicates if Write DQ leveling is enabled for frequency set 2. Bit[1] represents the support when non-initialization. Bit[0]represents the support when initialization. Reset Source: ctl_amod_g_rst_n
  [3:0] PI_WDQLVL_VREF_DELTA_F2 — The delta from the current Write DQ vref adjustment for non-initial wdq training for frequency set 2. Reset Source: ctl_amod_g_rst_n
0x2398 DDR16SS_CTLPHY_WRAP_CTL_CFG_CTLCFG_DENALI_PI_230
  [25:24] PI_RD_DBI_LEVEL_EN_F1 — Read DBI leveling enable, only can be enabled when READ DBI supported for DDR4, and PI_WDQLVL_EN or PI_RDLVL_EN configured by 1 for frequency set 1. Bit[1] represents the support when non-initialization. Bit[0]represents the support when initialization. Reset Source: ctl_amod_g_rst_n
  [17:16] PI_RD_DBI_LEVEL_EN_F0 — Read DBI leveling enable, only can be enabled when READ DBI supported for DDR4, and PI_WDQLVL_EN or PI_RDLVL_EN configured by 1 for frequency set 0. Bit[1] represents the support when non-initialization. Bit[0]represents the support when initialization. Reset Source: ctl_amod_g_rst_n
  [15:8] PI_WDQLVL_WRLAT_ADJ_F2 — Adjusted Tdfi_wrdata_en value for PHY read timing when read dbi disabled for frequency set 2, used for WDQ training. Reset Source: ctl_amod_g_rst_n
  [7:0] PI_WDQLVL_RDLAT_ADJ_F2 — Adjusted Tdfi_rddata_en value for PHY read timing when read dbi disabled for frequency set 2, used for WDQ training. Reset Source: ctl_amod_g_rst_n
0x239C DDR16SS_CTLPHY_WRAP_CTL_CFG_CTLCFG_DENALI_PI_231
  [31:24] PI_TRCD_F0 — DRAM tRCD value in cycles for frequency set 0. Reset Source: ctl_amod_g_rst_n
  [23:16] PI_TRP_F0 — DRAM tRP value in cycles for frequency set 0. Reset Source: ctl_amod_g_rst_n
  [15:8] PI_TRTP_F0 — DRAM tRTP value in cycles for frequency set 0. Reset Source: ctl_amod_g_rst_n
  [1:0] PI_RD_DBI_LEVEL_EN_F2 — Read DBI leveling enable, only can be enabled when READ DBI supported for DDR4, and PI_WDQLVL_EN or PI_RDLVL_EN configured by 1 for frequency set 2. Bit[1] represents the support when non-initialization. Bit[0]represents the support when initialization. Reset Source: ctl_amod_g_rst_n
0x23A0 DDR16SS_CTLPHY_WRAP_CTL_CFG_CTLCFG_DENALI_PI_232
  [23:16] PI_TWR_F0 — DRAM tWR value in cycles for frequency set 0. Reset Source: ctl_amod_g_rst_n
  [13:8] PI_TWTR_F0 — DRAM tWTR value in cycles for frequency set 0. Reset Source: ctl_amod_g_rst_n
  [4:0] PI_TCCD_L_F0 — DRAM CAS-to_CAS value within the same bank group in cycles for frequency set 0. Reset Source: ctl_amod_g_rst_n
0x23A4 DDR16SS_CTLPHY_WRAP_CTL_CFG_CTLCFG_DENALI_PI_233
  [19:0] PI_TRAS_MAX_F0 — DRAM tRAS_MAX value in cycles for frequency set 0. Reset Source: ctl_amod_g_rst_n
0x23A8 DDR16SS_CTLPHY_WRAP_CTL_CFG_CTLCFG_DENALI_PI_234
  [29:24] PI_TCCDMW_F0 — LPDDR4 DRAM tCCDMW in cycles for frequency set 0. Reset Source: ctl_amod_g_rst_n
  [19:16] PI_TDQSCK_MAX_F0 — Additional delay needed for tDQSCK for frequency set 0. Reset Source: ctl_amod_g_rst_n
  [8:0] PI_TRAS_MIN_F0 — DRAM tRAS_MIN value in cycles for frequency set 0. Reset Source: ctl_amod_g_rst_n
